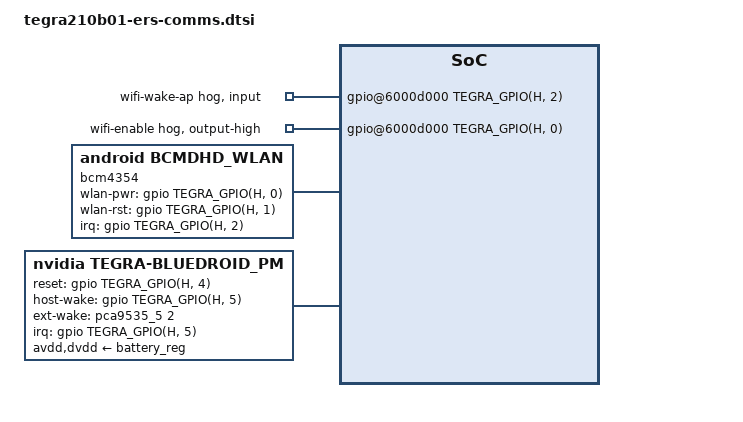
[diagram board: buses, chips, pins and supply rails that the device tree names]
/*
 * Copyright (c) 2017, NVIDIA CORPORATION.  All rights reserved.
 *
 * This program is free software; you can redistribute it and/or modify
 * it under the terms of the GNU General Public License as published by
 * the Free Software Foundation; version 2 of the License.
 *
 * This program is distributed in the hope that it will be useful, but WITHOUT
 * ANY WARRANTY; without even the implied warranty of MERCHANTABILITY or
 * FITNESS FOR A PARTICULAR PURPOSE.  See the GNU General Public License for
 * more details.
 *
 * You should have received a copy of the GNU General Public License along
 * with this program; if not, write to the Free Software Foundation, Inc.,
 * 51 Franklin Street, Fifth Floor, Boston, MA  02110-1301, USA.
 *
 */
#include <dt-bindings/gpio/tegra-gpio.h>

/ {
	gpio@6000d000 {
		wifi-wake-ap {
			gpio-hog;
			gpios = <TEGRA_GPIO(H, 2) 0>;
			input;
			label = "wifi-wake-ap";
		};
		wifi-enable {
			gpio-hog;
			gpios = <TEGRA_GPIO(H, 0) 0>;
			output-high;
			label = "wifi-enable";
		};
	};

	bcm4354: bcmdhd_wlan {
		compatible = "android,bcmdhd_wlan";
		pwr-retry-cnt = <0>;
		interrupt-parent = <&gpio>;
		interrupts = <TEGRA_GPIO(H, 2) 0x14>;
		nvidia,pmc-wakeup = <&tegra_pmc
				PMC_WAKE_TYPE_EVENT 8 PMC_TRIGGER_TYPE_HIGH>;
		wlan-pwr-gpio = <&gpio TEGRA_GPIO(H, 0) 0>;
		wlan-rst-gpio = <&gpio TEGRA_GPIO(H, 1) 0>;
		fw_path = "/vendor/firmware/bcm4354/fw_bcmdhd.bin";
		nv_path = "/vendor/firmware/nvram_4354.txt";
		sdhci-host = <&sdhci1>;
		status = "okay";
	};

	bluedroid_pm {
		compatible = "nvidia,tegra-bluedroid_pm";
		id = <0>;
		bluedroid_pm,reset-gpio = <&gpio TEGRA_GPIO(H, 4) 0>;
		bluedroid_pm,host-wake-gpio = <&gpio TEGRA_GPIO(H, 5) 0>;
		bluedroid_pm,ext-wake-gpio = <&pca9535_5 2 GPIO_ACTIVE_HIGH>;
		avdd-supply = <&battery_reg>;
		dvdd-supply = <&battery_reg>;
		interrupt-parent = <&gpio>;
		interrupts = <TEGRA_GPIO(H, 5) 0x01>;
		nvidia,pmc-wakeup = <&tegra_pmc
				PMC_WAKE_TYPE_EVENT 52 (PMC_TRIGGER_TYPE_RISING | PMC_TRIGGER_TYPE_FALLING)>;
	};

};
